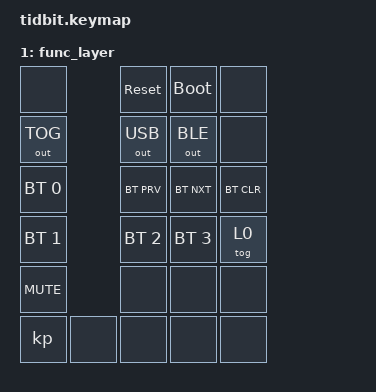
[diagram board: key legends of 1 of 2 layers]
/*
 * Copyright (c) 2020 The ZMK Contributors
 *
 * SPDX-License-Identifier: MIT
 */

#include <behaviors.dtsi>
#include <dt-bindings/zmk/bt.h>
#include <dt-bindings/zmk/keys.h>
#include <dt-bindings/zmk/outputs.h>

/

    keymap {
        compatible = "zmk,keymap";

        default_layer {
            bindings = <
&kp ESC          &kp TAB          &kp BACKSPACE    &kp LEFT_SHIFT
&kp KP_NUMLOCK   &kp KP_DIVIDE    &kp KP_MULTIPLY  &kp KP_EQUAL
&kp KP_NUMBER_7  &kp KP_NUMBER_8  &kp KP_NUMBER_9  &kp KP_MINUS
&kp KP_NUMBER_4  &kp KP_NUMBER_5  &kp KP_NUMBER_6  &kp RS(KP_PLUS)
&kp KP_NUMBER_1  &kp KP_NUMBER_2  &kp KP_NUMBER_3  &lt 1 KP_ENTER
&kp KP_NUMBER_0  &kp KP_NUMBER_0  &kp KP_DOT       &none
            >;

        };

        func_layer {
            bindings = <
&none         &sys_reset    &bootloader   &none
&out OUT_TOG  &out OUT_USB  &out OUT_BLE  &none
&bt BT_SEL 0  &bt BT_PRV    &bt BT_NXT    &bt BT_CLR
&bt BT_SEL 1  &bt BT_SEL 2  &bt BT_SEL 3  &tog 0
&kp C_MUTE    &none         &none         &none
&kp &none     &none         &none         &none
            >;

        };
    };
};
